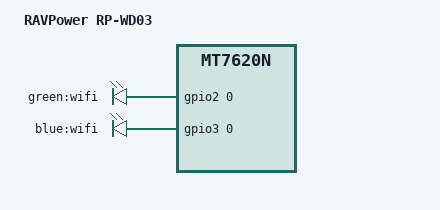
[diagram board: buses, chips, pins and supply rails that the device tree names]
#include "mt7620n_sunvalley_filehub.dtsi"

/ {
	compatible = "ravpower,rp-wd03", "ralink,mt7620n-soc";
	model = "RAVPower RP-WD03";

	aliases {
		led-boot = &led_wifi_blue;
		led-failsafe = &led_wifi_blue;
		led-running = &led_wifi_blue;
		led-upgrade = &led_wifi_blue;
	};

	leds {
		compatible = "gpio-leds";

		wifi_green {
			label = "green:wifi";
			gpios = <&gpio2 0 GPIO_ACTIVE_HIGH>;
		};

		led_wifi_blue: wifi_blue {
			label = "blue:wifi";
			gpios = <&gpio3 0 GPIO_ACTIVE_HIGH>;
		};
	};
};
